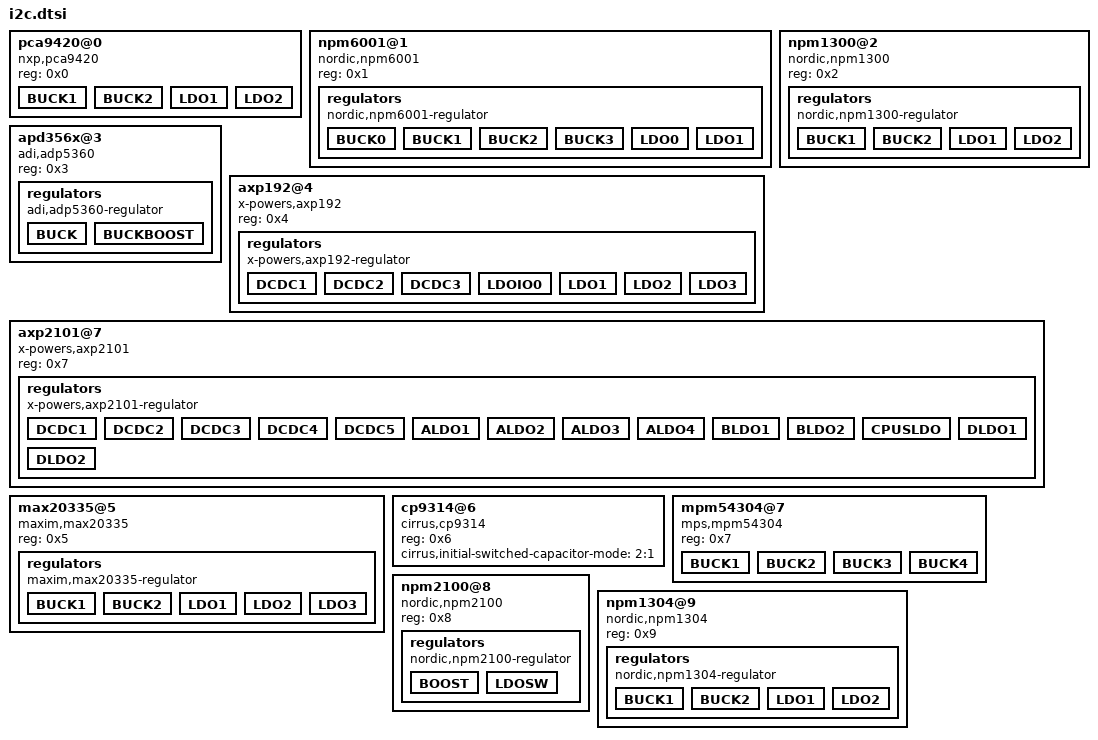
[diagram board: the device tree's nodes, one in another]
/*
 * Copyright (c) 2023 Nordic Semiconductor ASA
 * SPDX-License-Identifier: Apache-2.0
 */

/****************************************
 * PLEASE KEEP REG ADDRESSES SEQUENTIAL *
 **************************************
 */

pca9420@0 {
	compatible = "nxp,pca9420";
	reg = <0x0>;

	BUCK1 {};
	BUCK2 {};
	LDO1 {};
	LDO2 {};
};

npm6001@1 {
	compatible = "nordic,npm6001";
	reg = <0x1>;

	regulators {
		compatible = "nordic,npm6001-regulator";

		BUCK0 {};
		BUCK1 {};
		BUCK2 {};
		BUCK3 {};
		LDO0 {};
		LDO1 {};
	};
};

npm1300@2 {
	compatible = "nordic,npm1300";
	reg = <0x2>;

	regulators {
		compatible = "nordic,npm1300-regulator";

		BUCK1 {};
		BUCK2 {};
		LDO1 {};
		LDO2 {};
	};
};

apd356x@3 {
	compatible = "adi,adp5360";
	reg = <0x3>;

	regulators {
		compatible = "adi,adp5360-regulator";

		BUCK {};
		BUCKBOOST {};
	};
};

axp192@4 {
	compatible = "x-powers,axp192";
	reg = <0x4>;

	regulators {
		compatible = "x-powers,axp192-regulator";

		DCDC1 {};
		DCDC2 {};
		DCDC3 {};
		LDOIO0 {};
		LDO1 {};
		LDO2 {};
		LDO3 {};
	};
};

axp2101@7 {
	compatible = "x-powers,axp2101";
	reg = <0x7>;

	regulators {
		compatible = "x-powers,axp2101-regulator";

		DCDC1 {};
		DCDC2 {};
		DCDC3 {};
		DCDC4 {};
		DCDC5 {};
		ALDO1 {};
		ALDO2 {};
		ALDO3 {};
		ALDO4 {};
		BLDO1 {};
		BLDO2 {};
		CPUSLDO {};
		DLDO1 {};
		DLDO2 {};
	};
};

max20335@5 {
	compatible = "maxim,max20335";
	reg = <0x5>;

	regulators {
		compatible = "maxim,max20335-regulator";

		BUCK1 {};
		BUCK2 {};
		LDO1 {};
		LDO2 {};
		LDO3 {};
	};
};

cp9314@6 {
	compatible = "cirrus,cp9314";
	reg = <0x6>;

	cirrus,initial-switched-capacitor-mode = "2:1";
};

mpm54304@7 {
	compatible = "mps,mpm54304";
	reg = <0x7>;

	BUCK1 {};
	BUCK2 {};
	BUCK3 {};
	BUCK4 {};
};

npm2100@8 {
	compatible = "nordic,npm2100";
	reg = <0x8>;

	regulators {
		compatible = "nordic,npm2100-regulator";

		BOOST {};
		LDOSW {};
	};
};

npm1304@9 {
	compatible = "nordic,npm1304";
	reg = <0x9>;

	regulators {
		compatible = "nordic,npm1304-regulator";

		BUCK1 {};
		BUCK2 {};
		LDO1 {};
		LDO2 {};
	};
};
